# N32H49X register map
Vendor: Nsingtech Ltd.; File version: 1.0
Registers are 32-bit, read-write, reset 0x0 unless marked. A register's access mark holds for its fields unless they carry their own. Offsets are from the block's base; [hi:lo] are bit positions; 'fields as' and 'values as' point back to an identical list.

## BTIM1 — Basic timer
Base 0x40003C00
Same registers: BTIM2 0x40004000
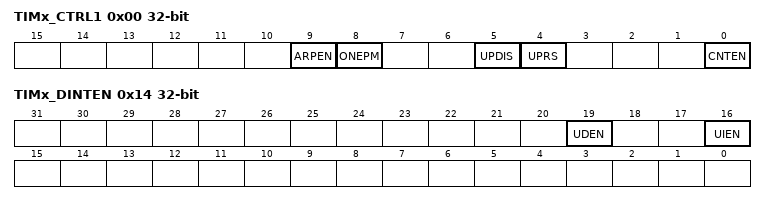
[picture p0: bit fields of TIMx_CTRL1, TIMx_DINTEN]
0x00 TIMx_CTRL1
  [9] ARPEN, [8] ONEPM, [5] UPDIS, [4] UPRS, [0] CNTEN
0x04 TIMx_CTRL2
  [15:12] MMSEL
0x08 TIMx_STS
  [16] UDITF
0x0C TIMx_EVTGEN
  [8] UDGN
0x14 TIMx_DINTEN
  [19] UDEN, [16] UIEN
0x40 TIMx_PSC
  [15:0] PSC
0x44 TIMx_AR reset 0xFFFFFFFF
0x48 TIMx_CNT

## SDRAM — Synchronous dynamic random access memory controller
Base 0x40027000
0x80 SDRAM_BADD1 — Base Address for SDRAM1 Register
  [31:12] ADDBASE
0x84 SDRAM_ADDMASK1 — Address Mask for SDRAM1 Register
  [31:12] ADDMASK
0x88 SDRAM_BADD2 — Base Address for SDRAM2 Register
  [31:12] ADDBASE
0x8C SDRAM_ADDMASK2 — Address Mask for SDRAM2 Register
  [31:12] ADDMASK
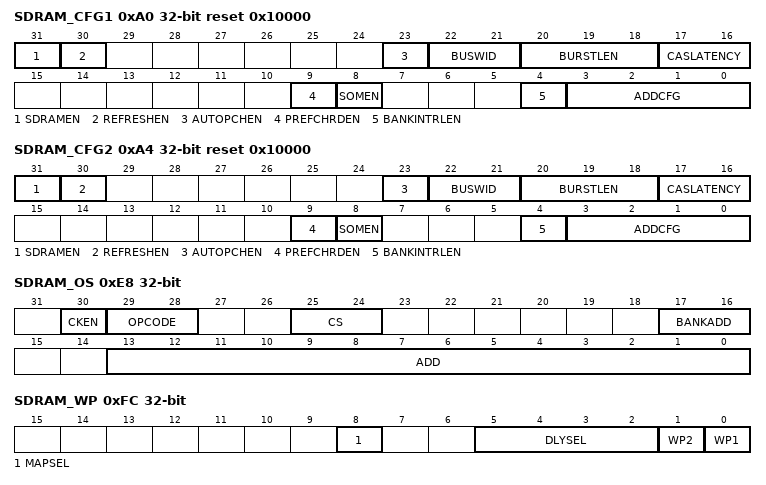
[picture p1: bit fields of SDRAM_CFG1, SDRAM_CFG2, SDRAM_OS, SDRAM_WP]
0xA0 SDRAM_CFG1 reset 0x10000 — SDRAM1 Configuration Register
  [31] SDRAMEN, [30] REFRESHEN, [23] AUTOPCHEN, [22:21] BUSWID, [20:18] BURSTLEN, [17:16] CASLATENCY, [9] PREFCHRDEN, [8] SOMEN, [4] BANKINTRLEN, [3:0] ADDCFG
0xA4 SDRAM_CFG2 reset 0x10000 — SDRAM2 Configuration Register
  fields as SDRAM_CFG1
0xB0 SDRAM_RAT — Row Active Time Register
  [5:0] TRAS
0xB4 SDRAM_RCT — Row Cycle Time Register
  [5:0] TRC
0xB8 SDRAM_RRDLY — Row Active to Row Active Delay Register
  [5:0] TRRD
0xBC SDRAM_PT — Precharge Time Register
  [5:0] TRP
0xC0 SDRAM_WRT — Write Recovery Time Register
  [5:0] TWR
0xC4 SDRAM_RFCT — Refresh Cycle Time Register
  [5:0] TRFC
0xC8 SDRAM_RCDLY — RAS to CAS Delay Register
  [3:0] TRCD
0xCC SDRAM_RI — Refresh Interval Register
  [23:0] TRI
0xE0 SDRAM_CBO — Synchronous Memory Buffer Operation Register
  [31:0] DUMMY
0xE4 SDRAM_OR — SDRAM Operation Request Register
  [31:0] DUMMY
0xE8 SDRAM_OS — SDRAM Operation Setup Register
  [30] CKEN, [29:28] OPCODE, [25:24] CS, [17:16] BANKADD, [13:0] ADD
0xFC SDRAM_WP — Write Protection Register
  [8] MAPSEL, [5:2] DLYSEL, [1] WP2, [0] WP1

## I2C1 — Inter integrated circuit
Base 0x40001C00
Same registers: I2C2 0x40002000, I2C3 0x40007400, I2C4 0x40007800
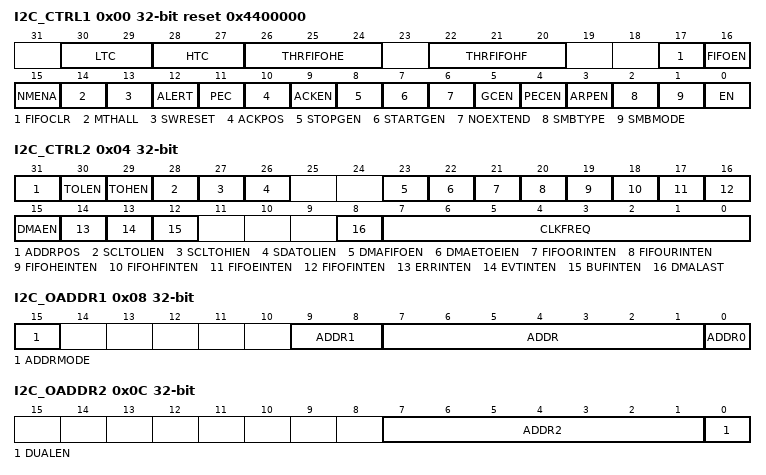
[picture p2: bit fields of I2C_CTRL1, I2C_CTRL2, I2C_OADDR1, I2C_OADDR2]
0x00 I2C_CTRL1 reset 0x4400000
  [30:29] LTC, [28:27] HTC, [26:24] THRFIFOHE, [22:20] THRFIFOHF, [17] FIFOCLR, [16] FIFOEN, [15] NMENA, [14] MTHALL, [13] SWRESET, [12] ALERT, [11] PEC, [10] ACKPOS, [9] ACKEN, [8] STOPGEN, [7] STARTGEN, [6] NOEXTEND, [5] GCEN, [4] PECEN, [3] ARPEN, [2] SMBTYPE, [1] SMBMODE, [0] EN
0x04 I2C_CTRL2
  [31] ADDRPOS, [30] TOLEN, [29] TOHEN, [28] SCLTOLIEN, [27] SCLTOHIEN, [26] SDATOLIEN, [23] DMAFIFOEN, [22] DMAETOEIEN, [21] FIFOORINTEN, [20] FIFOURINTEN, [19] FIFOHEINTEN, [18] FIFOHFINTEN, [17] FIFOEINTEN, [16] FIFOFINTEN, [15] DMAEN, [14] ERRINTEN, [13] EVTINTEN, [12] BUFINTEN, [8] DMALAST, [7:0] CLKFREQ
0x08 I2C_OADDR1
  [15] ADDRMODE, [9:8] ADDR1, [7:1] ADDR, [0] ADDR0
0x0C I2C_OADDR2
  [7:1] ADDR2, [0] DUALEN
0x10 I2C_DAT
  [7:0] DATA
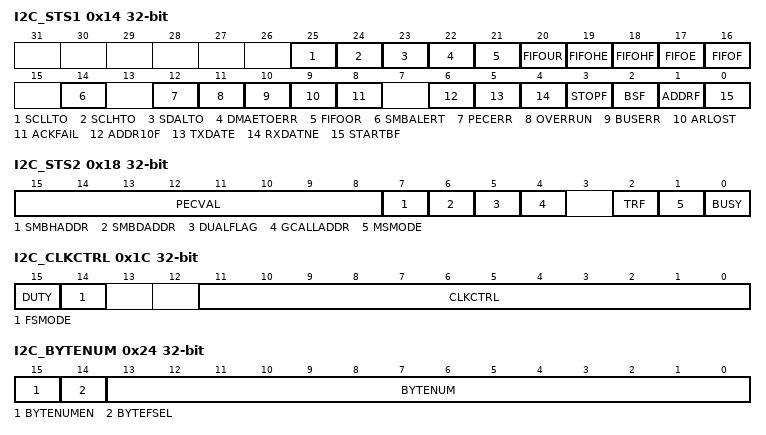
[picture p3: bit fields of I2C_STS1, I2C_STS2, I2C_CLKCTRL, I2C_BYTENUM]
0x14 I2C_STS1
  [25] SCLLTO, [24] SCLHTO, [23] SDALTO, [22] DMAETOERR, [21] FIFOOR, [20] FIFOUR, [19] FIFOHE, [18] FIFOHF, [17] FIFOE, [16] FIFOF, [14] SMBALERT, [12] PECERR, [11] OVERRUN, [10] BUSERR, [9] ARLOST, [8] ACKFAIL, [6] ADDR10F, [5] TXDATE, [4] RXDATNE, [3] STOPF, [2] BSF, [1] ADDRF, [0] STARTBF
0x18 I2C_STS2
  [15:8] PECVAL, [7] SMBHADDR, [6] SMBDADDR, [5] DUALFLAG, [4] GCALLADDR, [2] TRF, [1] MSMODE, [0] BUSY
0x1C I2C_CLKCTRL
  [15] DUTY, [14] FSMODE, [11:0] CLKCTRL
0x20 I2C_TMRISE reset 0x2
  [7:0] TMRISE
0x24 I2C_BYTENUM
  [15] BYTENUMEN, [14] BYTEFSEL, [13:0] BYTENUM
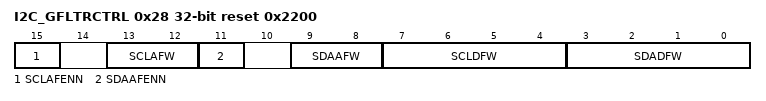
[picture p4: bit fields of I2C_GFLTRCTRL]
0x28 I2C_GFLTRCTRL reset 0x2200
  [15] SCLAFENN, [13:12] SCLAFW, [11] SDAAFENN, [9:8] SDAAFW, [7:4] SCLDFW, [3:0] SDADFW
0x2C I2C_FIFODAT
  [7:0] FIFODAT

## IWDG — Independent watchdog
Base 0x40001800
0x00 IWDG_KEY
  [15:0] KEYV
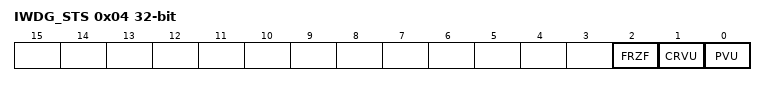
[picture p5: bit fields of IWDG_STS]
0x04 IWDG_STS (reset mask 0x3)
  [2] FRZF, [1] CRVU, [0] PVU
0x08 IWDG_PREDIV
  [2:0] PD
0x0C IWDG_RELV reset 0xFFF
  [11:0] REL
